AUTOSAR XML (schema 4.0)
package /S06API/If
  sender receiver interface VinCmd
    data val
  sender receiver interface IgnCmd
    data val
package /S06API/Swc
  application sw component type CloudApi
    provide port apiToCmdOut: provided-interface=VinCmd
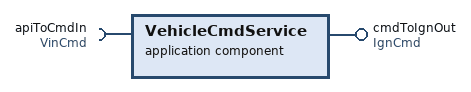
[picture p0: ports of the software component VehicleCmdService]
  application sw component type VehicleCmdService
    provide port cmdToIgnOut: provided-interface=IgnCmd
    require port apiToCmdIn: required-interface=VinCmd
  application sw component type IgnitionCtrl
    require port cmdToIgnIn: required-interface=IgnCmd
  composition sw component type Root
    component api: type=CloudApi
    component cmdsvc: type=VehicleCmdService
    component ignition: type=IgnitionCtrl
    connect api.apiToCmdOut -> cmdsvc.apiToCmdIn
    connect cmdsvc.cmdToIgnOut -> ignition.cmdToIgnIn
package /S06API/Comm
  pdu apiToCmdIPdu
    signal apiToCmdISig: system signal apiToCmdSSig
  secured i pdu apiToCmdSecuredIPdu: auth-info-tx-length=32, freshness-value-id=1, freshness-value-length=8, payload=apiToCmdIPdu
  pdu cmdToIgnIPdu
    signal cmdToIgnISig: system signal cmdToIgnSSig
  secured i pdu cmdToIgnSecuredIPdu: auth-info-tx-length=32, freshness-value-id=1, freshness-value-length=8, payload=cmdToIgnIPdu
package /S06API/Topology
  ecu instance GatewayEcu
  ecu instance PowertrainEcu
  ecu instance TelematicsEcu
  system Veh
    root-software-compositions:
      root sw composition prototype Root: software-composition=Root
    system mapping Map
      data-mappings:
        data-element=Root.apiToCmdOut.val, system-signal=apiToCmdSSig
        data-element=Root.cmdToIgnOut.val, system-signal=cmdToIgnSSig
      sw-mappings:
        swc to ecu mapping ToGatewayEcu: component=cmdsvc, ecu-instance=GatewayEcu
        swc to ecu mapping ToPowertrainEcu: component=ignition, ecu-instance=PowertrainEcu
        swc to ecu mapping ToTelematicsEcu: component=api, ecu-instance=TelematicsEcu
